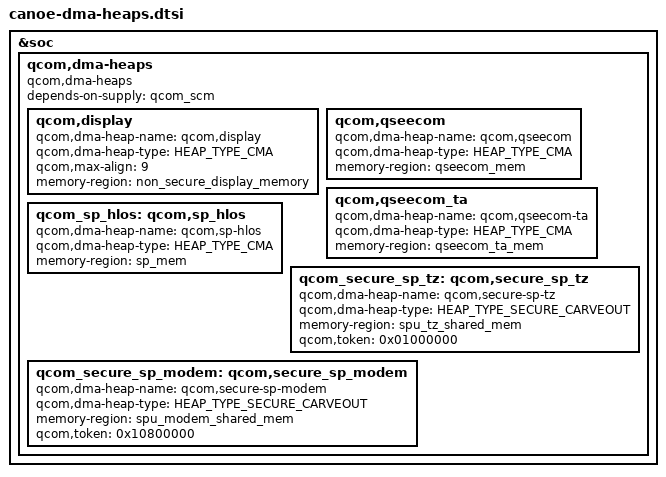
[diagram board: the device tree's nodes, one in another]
// SPDX-License-Identifier: BSD-3-Clause
/*
 * Copyright (c) 2024-2025 Qualcomm Innovation Center, Inc. All rights reserved.
 */

#include <dt-bindings/arm/msm/qcom_dma_heap_dt_constants.h>

&soc {
	qcom,dma-heaps {
		compatible = "qcom,dma-heaps";
		depends-on-supply = <&qcom_scm>;

		qcom,display {
			qcom,dma-heap-name = "qcom,display";
			qcom,dma-heap-type = <HEAP_TYPE_CMA>;
			qcom,max-align = <9>;
			memory-region = <&non_secure_display_memory>;
		};

		qcom,qseecom {
			qcom,dma-heap-name = "qcom,qseecom";
			qcom,dma-heap-type = <HEAP_TYPE_CMA>;
			memory-region = <&qseecom_mem>;
		};

		qcom,qseecom_ta {
			qcom,dma-heap-name = "qcom,qseecom-ta";
			qcom,dma-heap-type = <HEAP_TYPE_CMA>;
			memory-region = <&qseecom_ta_mem>;
		};

		qcom_sp_hlos: qcom,sp_hlos {
			qcom,dma-heap-name = "qcom,sp-hlos";
			qcom,dma-heap-type = <HEAP_TYPE_CMA>;
			memory-region = <&sp_mem>;
		};

		qcom_secure_sp_tz: qcom,secure_sp_tz {
			qcom,dma-heap-name = "qcom,secure-sp-tz";
			qcom,dma-heap-type = <HEAP_TYPE_SECURE_CARVEOUT>;
			memory-region = <&spu_tz_shared_mem>;
			qcom,token = <0x01000000>;
		};

		qcom_secure_sp_modem: qcom,secure_sp_modem {
			qcom,dma-heap-name = "qcom,secure-sp-modem";
			qcom,dma-heap-type = <HEAP_TYPE_SECURE_CARVEOUT>;
			memory-region = <&spu_modem_shared_mem>;
			qcom,token = <0x10800000>;
		};
	};
};
